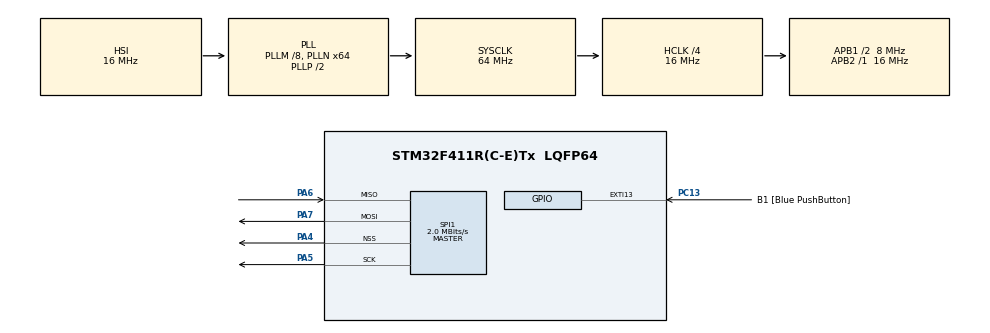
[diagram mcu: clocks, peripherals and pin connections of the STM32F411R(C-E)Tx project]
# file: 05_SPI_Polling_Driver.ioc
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Mcu.Family=STM32F4
Mcu.Name=STM32F411R(C-E)Tx
Mcu.Package=LQFP64
NVIC.PriorityGroup=NVIC_PRIORITYGROUP_0
PA13.GPIO_Label=TMS
PA13.Mode=Serial_Wire
PA13.Signal=SYS_JTMS-SWDIO
PA14.GPIO_Label=TCK
PA14.Mode=Serial_Wire
PA14.Signal=SYS_JTCK-SWCLK
PA4.Mode=NSS_Signal_Hard_Output
PA4.Signal=SPI1_NSS
PA5.Mode=Full_Duplex_Master
PA5.Signal=SPI1_SCK
PA6.Mode=Full_Duplex_Master
PA6.Signal=SPI1_MISO
PA7.Mode=Full_Duplex_Master
PA7.Signal=SPI1_MOSI
PB3.GPIO_Label=SWO
PB3.Signal=SYS_JTDO-SWO
PC13-ANTI_TAMP.GPIO_Label=B1 [Blue PushButton]
PC13-ANTI_TAMP.GPIO_ModeDefaultEXTI=GPIO_MODE_IT_FALLING
PC13-ANTI_TAMP.Signal=GPXTI13
PC14-OSC32_IN.Mode=LSE-External-Oscillator
PC14-OSC32_IN.Signal=RCC_OSC32_IN
PC15-OSC32_OUT.Mode=LSE-External-Oscillator
PC15-OSC32_OUT.Signal=RCC_OSC32_OUT
PH0\ -\ OSC_IN.Mode=HSE-External-Clock-Source
PH0\ -\ OSC_IN.Signal=RCC_OSC_IN
PH1\ -\ OSC_OUT.Mode=HSE-External-Clock-Source
PH1\ -\ OSC_OUT.Signal=RCC_OSC_OUT
ProjectManager.HeapSize=0x200
ProjectManager.StackSize=0x400
ProjectManager.TargetToolchain=STM32CubeIDE
RCC.48MHZClocksFreq_Value=32000000
RCC.AHBCLKDivider=RCC_SYSCLK_DIV4
RCC.AHBFreq_Value=16000000
RCC.APB1CLKDivider=RCC_HCLK_DIV2
RCC.APB1Freq_Value=8000000
RCC.APB1TimFreq_Value=16000000
RCC.APB2Freq_Value=16000000
RCC.APB2TimFreq_Value=16000000
RCC.CortexFreq_Value=16000000
RCC.FLatency-AdvancedSettings=FLASH_LATENCY_0
RCC.HCLKFreq_Value=16000000
RCC.HSE_VALUE=8000000
RCC.HSI_VALUE=16000000
RCC.PLLM=8
RCC.PLLN=64
RCC.SYSCLKFreq_VALUE=64000000
RCC.SYSCLKSource=RCC_SYSCLKSOURCE_PLLCLK
RCC.VCOOutputFreq_Value=128000000
SPI1.BaudRatePrescaler=SPI_BAUDRATEPRESCALER_8
SPI1.CalculateBaudRate=2.0 MBits/s
SPI1.DataSize=SPI_DATASIZE_8BIT
SPI1.Direction=SPI_DIRECTION_2LINES
SPI1.Mode=SPI_MODE_MASTER
SPI1.VirtualNSS=VM_NSSHARD
SPI1.VirtualType=VM_MASTER
board=NUCLEO-F411RE

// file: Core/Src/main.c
/* USER CODE BEGIN Header */
/**
  ******************************************************************************
  * @file           : main.c
  * @brief          : Main program body
  ******************************************************************************
  * @attention
  *
  * Copyright (c) 2024 STMicroelectronics.
  * All rights reserved.
  *
  * This software is licensed under terms that can be found in the LICENSE file
  * in the root directory of this software component.
  * If no LICENSE file comes with this software, it is provided AS-IS.
  *
  ******************************************************************************
  */
/* USER CODE END Header */
#include "main.h"
#include "spi.h"
#include "gpio.h"

/* USER CODE BEGIN PD */
uint8_t tx_data[5] = {1, 2, 3, 4, 5};
uint8_t rx_data[5];
/* USER CODE END PD */

void SystemClock_Config(void);

int main(void)
{

  /* MCU Configuration--------------------------------------------------------*/

  /* Reset of all peripherals, Initializes the Flash interface and the Systick. */
  HAL_Init();

  /* Configure the system clock */
  SystemClock_Config();

  /* Initialize all configured peripherals */
  MX_GPIO_Init();
  MX_SPI1_Init();
  /* USER CODE BEGIN 2 */

  HAL_SPI_TransmitReceive(&hspi1, tx_data, rx_data, 5, HAL_MAX_DELAY);

  /* USER CODE END 2 */

  /* Infinite loop */
  while (1)
  {

  }
}

void SystemClock_Config(void)
{
  RCC_OscInitTypeDef RCC_OscInitStruct = {0};
  RCC_ClkInitTypeDef RCC_ClkInitStruct = {0};

  /** Configure the main internal regulator output voltage
  */
  __HAL_RCC_PWR_CLK_ENABLE();
  __HAL_PWR_VOLTAGESCALING_CONFIG(PWR_REGULATOR_VOLTAGE_SCALE1);

  /** Initializes the RCC Oscillators according to the specified parameters
  * in the RCC_OscInitTypeDef structure.
  */
  RCC_OscInitStruct.OscillatorType = RCC_OSCILLATORTYPE_HSI;
  RCC_OscInitStruct.HSIState = RCC_HSI_ON;
  RCC_OscInitStruct.HSICalibrationValue = RCC_HSICALIBRATION_DEFAULT;
  RCC_OscInitStruct.PLL.PLLState = RCC_PLL_ON;
  RCC_OscInitStruct.PLL.PLLSource = RCC_PLLSOURCE_HSI;
  RCC_OscInitStruct.PLL.PLLM = 8;
  RCC_OscInitStruct.PLL.PLLN = 64;
  RCC_OscInitStruct.PLL.PLLP = RCC_PLLP_DIV2;
  RCC_OscInitStruct.PLL.PLLQ = 4;
  if (HAL_RCC_OscConfig(&RCC_OscInitStruct) != HAL_OK)
  {
    Error_Handler();
  }

  /** Initializes the CPU, AHB and APB buses clocks
  */
  RCC_ClkInitStruct.ClockType = RCC_CLOCKTYPE_HCLK|RCC_CLOCKTYPE_SYSCLK
                              |RCC_CLOCKTYPE_PCLK1|RCC_CLOCKTYPE_PCLK2;
  RCC_ClkInitStruct.SYSCLKSource = RCC_SYSCLKSOURCE_PLLCLK;
  RCC_ClkInitStruct.AHBCLKDivider = RCC_SYSCLK_DIV4;
  RCC_ClkInitStruct.APB1CLKDivider = RCC_HCLK_DIV2;
  RCC_ClkInitStruct.APB2CLKDivider = RCC_HCLK_DIV1;

  if (HAL_RCC_ClockConfig(&RCC_ClkInitStruct, FLASH_LATENCY_0) != HAL_OK)
  {
    Error_Handler();
  }
}

void Error_Handler(void)
{
  __disable_irq();
  while (1)
  {
  }
}
